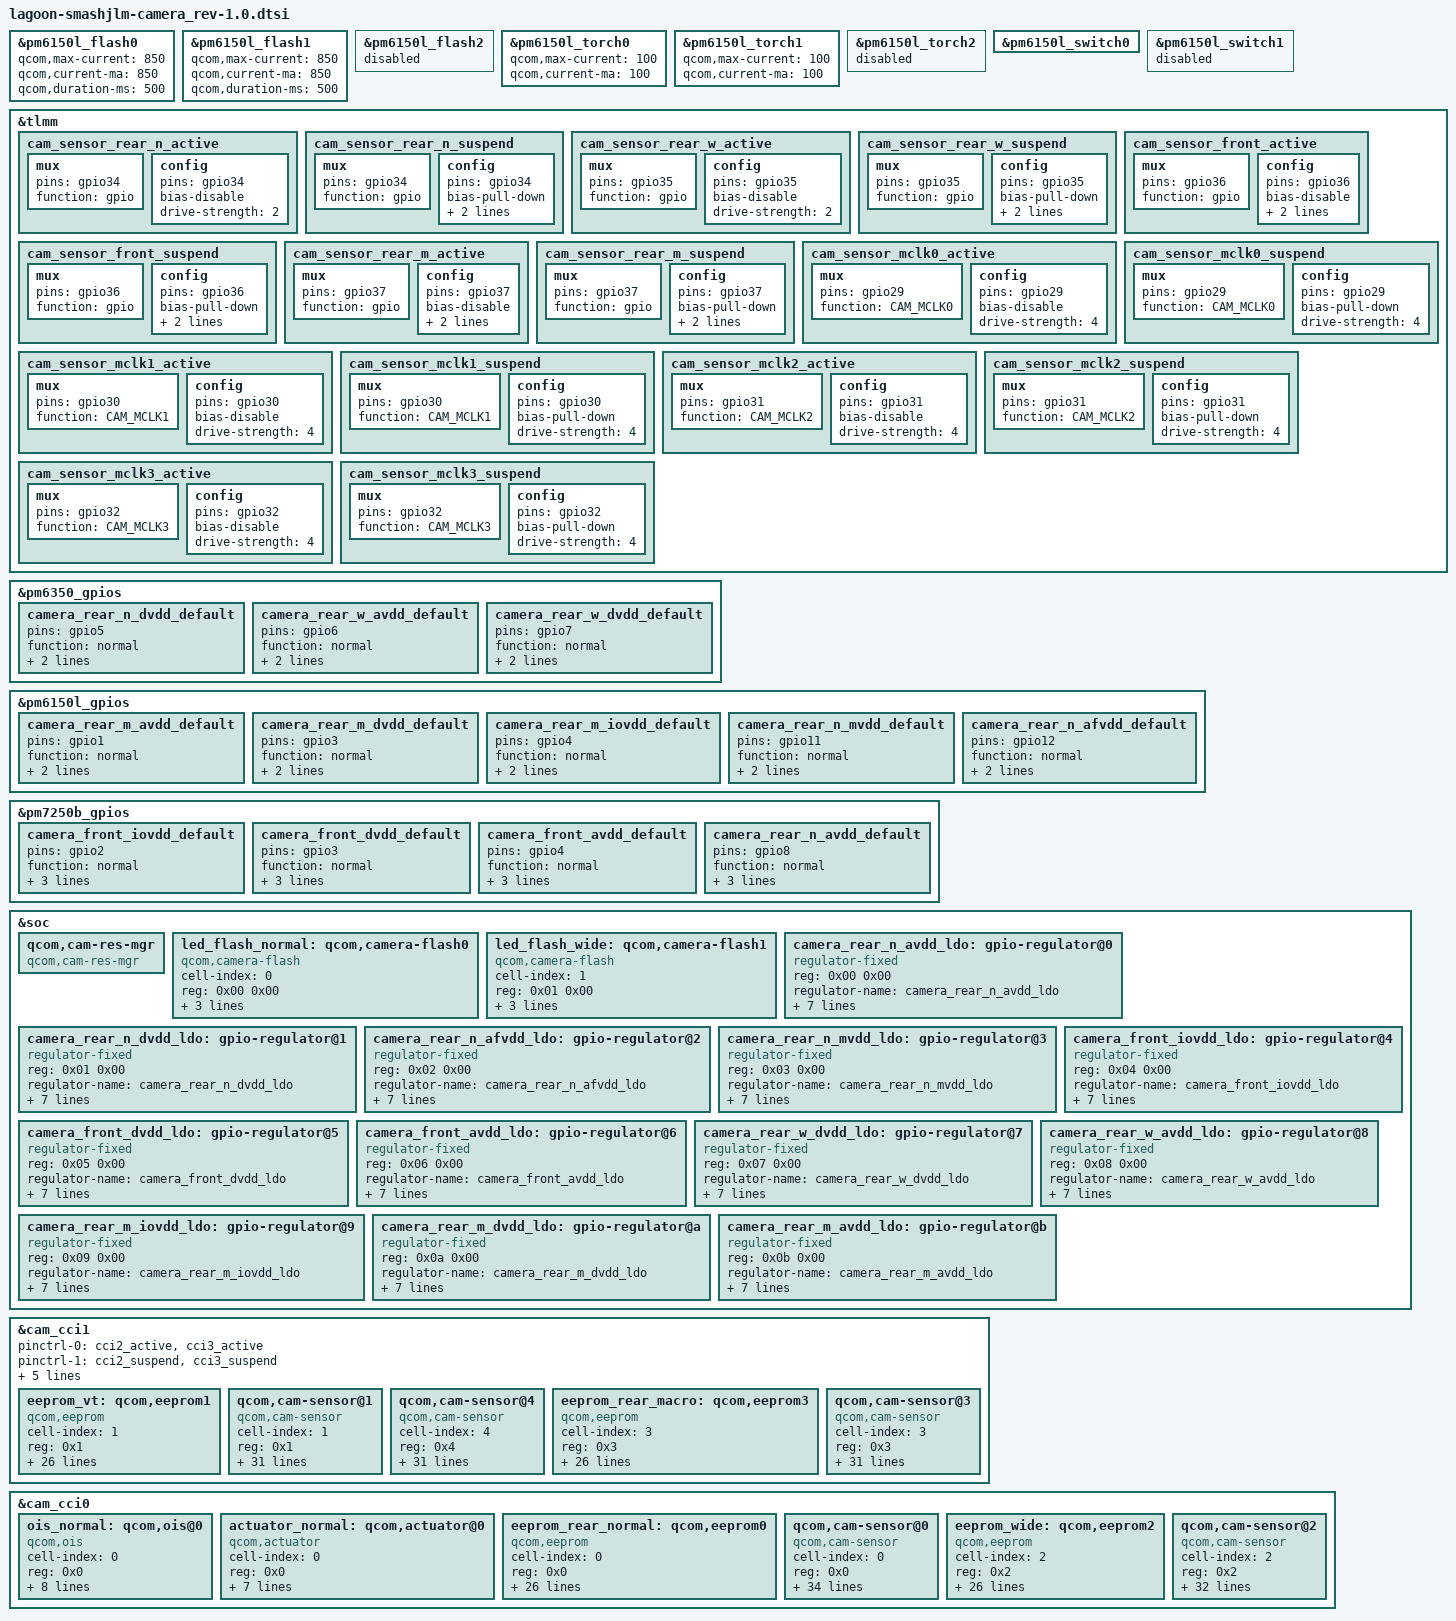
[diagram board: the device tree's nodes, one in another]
// SPDX-License-Identifier: GPL-2.0-only
/*
 * Copyright (c) 2018-2019, The Linux Foundation. All rights reserved.
 */

#include <dt-bindings/clock/qcom,camcc-lagoon.h>

&pm6150l_flash0 {
	status = "ok";
	qcom,max-current = <850>;
	qcom,current-ma = <850>;
	qcom,duration-ms = <500>;
};

&pm6150l_flash1 {
	status = "ok";
	qcom,max-current = <850>;
	qcom,current-ma = <850>;
	qcom,duration-ms = <500>;
};

&pm6150l_flash2 {
	status = "disabled";
};

&pm6150l_torch0 {
	status = "ok";
	qcom,max-current = <100>;
	qcom,current-ma = <100>;
};

&pm6150l_torch1 {
	status = "ok";
	qcom,max-current = <100>;
	qcom,current-ma = <100>;
};

&pm6150l_torch2 {
	status = "disabled";
};

&pm6150l_switch0 {
	status = "ok";
};

&pm6150l_switch1 {
	status = "disbled";
};

&tlmm{
	cam_sensor_rear_n_active: cam_sensor_rear_n_active {
		mux {
			pins = "gpio34";
			function = "gpio";
		};

		config {
			pins = "gpio34";
			bias-disable;
			drive-strength = <2>;
		};
	};

	cam_sensor_rear_n_suspend: cam_sensor_rear_n_suspend {
		mux {
			pins = "gpio34";
			function = "gpio";
		};

		config {
			pins = "gpio34";
			bias-pull-down;
			drive-strength = <2>;
			output-low;
		};
	};

	cam_sensor_rear_w_active: cam_sensor_rear_w_active {
		mux {
			pins = "gpio35";
			function = "gpio";
		};

		config {
			pins = "gpio35";
			bias-disable;
			drive-strength = <2>;
		};
	};

	cam_sensor_rear_w_suspend: cam_sensor_rear_w_suspend {
		mux {
			pins = "gpio35";
			function = "gpio";
		};

		config {
			pins = "gpio35";
			bias-pull-down;
			drive-strength = <2>;
			output-low;
		};
	};

	cam_sensor_front_active: cam_sensor_front_active {
		mux {
			pins = "gpio36";
			function = "gpio";
		};

		config {
			pins = "gpio36";
			bias-disable;
			drive-strength = <2>;
			output-low;
		};
	};

	cam_sensor_front_suspend: cam_sensor_front_suspend {
		mux {
			pins = "gpio36";
			function = "gpio";
		};

		config {
			pins = "gpio36";
			bias-pull-down;
			drive-strength = <2>;
			output-low;
		};
	};

	cam_sensor_rear_m_active: cam_sensor_rear_m_active {
		mux {
			pins = "gpio37";
			function = "gpio";
		};

		config {
			pins = "gpio37";
			bias-disable;
			drive-strength = <2>;
			output-low;
		};
	};

	cam_sensor_rear_m_suspend: cam_sensor_rear_m_suspend {
		mux {
			pins = "gpio37";
			function = "gpio";
		};

		config {
			pins = "gpio37";
			bias-pull-down;
			drive-strength = <2>;
			output-low;
		};
	};

	cam_sensor_mclk0_active: cam_sensor_mclk0_active {
		/* MCLK0 */
		mux {
			pins = "gpio29";
			function = "CAM_MCLK0";
		};

		config {
			pins = "gpio29";
			bias-disable; /* No PULL */
			drive-strength = <4>; /* To improve rising time (2ma->4ma)*/
		};
	};

	cam_sensor_mclk0_suspend: cam_sensor_mclk0_suspend {
		/* MCLK0 */
		mux {
			pins = "gpio29";
			function = "CAM_MCLK0";
		};

		config {
			pins = "gpio29";
			bias-pull-down; /* PULL DOWN */
			drive-strength = <4>; /* 4 MA */
		};
	};

	cam_sensor_mclk1_active: cam_sensor_mclk1_active {
		/* MCLK1 */
		mux {
			pins = "gpio30";
			function = "CAM_MCLK1";
		};

		config {
			pins = "gpio30";
			bias-disable; /* No PULL */
			drive-strength = <4>; /* 4 MA */
		};
	};

	cam_sensor_mclk1_suspend: cam_sensor_mclk1_suspend {
		/* MCLK1 */
		mux {
			pins = "gpio30";
			function = "CAM_MCLK1";
		};

		config {
			pins = "gpio30";
			bias-pull-down; /* PULL DOWN */
			drive-strength = <4>; /* 4 MA */
		};
	};

	cam_sensor_mclk2_active: cam_sensor_mclk2_active {
		/* MCLK2 */
		mux {
			pins = "gpio31";
			function = "CAM_MCLK2";
		};

		config {
			pins = "gpio31";
			bias-disable; /* No PULL */
			drive-strength = <4>; /* 4 MA */
		};
	};

	cam_sensor_mclk2_suspend: cam_sensor_mclk2_suspend {
		/* MCLK2 */
		mux {
			pins = "gpio31";
			function = "CAM_MCLK2";
		};

		config {
			pins = "gpio31";
			bias-pull-down; /* PULL DOWN */
			drive-strength = <4>; /* 4 MA */
		};
	};

	cam_sensor_mclk3_active: cam_sensor_mclk3_active {
		/* MCLK3 */
		mux {
			pins = "gpio32";
			function = "CAM_MCLK3";
		};

		config {
			pins = "gpio32";
			bias-disable; /* No PULL */
			drive-strength = <4>; /* 4 MA */
		};
	};

	cam_sensor_mclk3_suspend: cam_sensor_mclk3_suspend {
		/* MCLK3 */
		mux {
			pins = "gpio32";
			function = "CAM_MCLK3";
		};

		config {
			pins = "gpio32";
			bias-pull-down; /* PULL DOWN */
			drive-strength = <4>; /* 4 MA */
		};
	};
};

&pm6350_gpios {
	camera_rear_n_dvdd_default: camera_rear_n_dvdd_default {
		pins = "gpio5";
		function = "normal";
		power-source = <0>;
		output-high;
	};

	camera_rear_w_avdd_default: camera_rear_w_avdd_default {
		pins = "gpio6";
		function = "normal";
		power-source = <0>;
		output-high;
	};

	camera_rear_w_dvdd_default: camera_rear_w_dvdd_default {
		pins = "gpio7";
		function = "normal";
		power-source = <0>;
		output-high;
	};
};

&pm6150l_gpios {
	camera_rear_m_avdd_default: camera_rear_m_avdd_default {
		pins = "gpio1";
		function = "normal";
		power-source = <0>;
		output-high;
	};

	camera_rear_m_dvdd_default: camera_rear_m_dvdd_default {
		pins = "gpio3";
		function = "normal";
		power-source = <0>;
		output-high;
	};

	camera_rear_m_iovdd_default: camera_rear_m_iovdd_default {
		pins = "gpio4";
		function = "normal";
		power-source = <0>;
		output-high;
	};

	camera_rear_n_mvdd_default: camera_rear_n_mvdd_default {
		pins = "gpio11";
		function = "normal";
		power-source = <0>;
		output-high;
	};
	camera_rear_n_afvdd_default: camera_rear_n_afvdd_default {
		pins = "gpio12";
		function = "normal";
		power-source = <0>;
		output-high;
	};
};

&pm7250b_gpios {
	camera_front_iovdd_default: camera_front_iovdd_default {
		pins = "gpio2";
		function = "normal";
		power-source = <0>;
		input-disable;
		output-high;
	};

	camera_front_dvdd_default: camera_front_dvdd_default {
		pins = "gpio3";
		function = "normal";
		power-source = <0>;
		input-disable;
		output-high;
	};

	camera_front_avdd_default: camera_front_avdd_default {
		pins = "gpio4";
		function = "normal";
		power-source = <0>;
		input-disable;
		output-high;
	};

	camera_rear_n_avdd_default: camera_rear_n_avdd_default {
		pins = "gpio8";
		function = "normal";
		power-source = <0>;
		input-disable;
		output-high;
	};
};

&soc {
    qcom,cam-res-mgr {
        compatible = "qcom,cam-res-mgr";
        status = "ok";
    };

	led_flash_normal: qcom,camera-flash0 {
		cell-index = <0>;
		reg = <0x00 0x00>;
		compatible = "qcom,camera-flash";
		flash-source = <&pm6150l_flash0 &pm6150l_flash1>;
		torch-source = <&pm6150l_torch0 &pm6150l_torch1>;
		switch-source = <&pm6150l_switch2>;
		status = "ok";
	};

	led_flash_wide: qcom,camera-flash1 {
		cell-index = <1>;
		reg = <0x01 0x00>;
		compatible = "qcom,camera-flash";
		flash-source = <&pm6150l_flash0 &pm6150l_flash1>;
		torch-source = <&pm6150l_torch0 &pm6150l_torch1>;
		switch-source = <&pm6150l_switch2>;
		status = "ok";
	};

	camera_rear_n_avdd_ldo: gpio-regulator@0 {
		compatible = "regulator-fixed";
		reg = <0x00 0x00>;
		regulator-name = "camera_rear_n_avdd_ldo";
		regulator-min-microvolt = <2800000>;
		regulator-max-microvolt = <2800000>;
		regulator-enable-ramp-delay = <135>;
		enable-active-high;
		gpio = <&pm7250b_gpios 8 0>;
		pinctrl-names = "default";
		pinctrl-0 = <&camera_rear_n_avdd_default>;
		vin-supply = <&BOB>;
	};

	camera_rear_n_dvdd_ldo: gpio-regulator@1 {
		compatible = "regulator-fixed";
		reg = <0x01 0x00>;
		regulator-name = "camera_rear_n_dvdd_ldo";
		regulator-min-microvolt = <1050000>;
		regulator-max-microvolt = <1050000>;
		regulator-enable-ramp-delay = <135>;
		enable-active-high;
		gpio = <&pm6350_gpios 5 0>;
		pinctrl-names = "default";
		pinctrl-0 = <&camera_rear_n_dvdd_default>;
		vin-supply = <&S2A>;
	};

	camera_rear_n_afvdd_ldo: gpio-regulator@2 {
		compatible = "regulator-fixed";
		reg = <0x02 0x00>;
		regulator-name = "camera_rear_n_afvdd_ldo";
		regulator-min-microvolt = <2800000>;
		regulator-max-microvolt = <2800000>;
		regulator-enable-ramp-delay = <135>;
		enable-active-high;
		gpio = <&pm6150l_gpios 12 0>;
		pinctrl-names = "default";
		pinctrl-0 = <&camera_rear_n_afvdd_default>;
		vin-supply = <&BOB>;
	};

	camera_rear_n_mvdd_ldo: gpio-regulator@3 {
		compatible = "regulator-fixed";
		reg = <0x03 0x00>;
		regulator-name = "camera_rear_n_mvdd_ldo";
		regulator-min-microvolt = <2800000>;
		regulator-max-microvolt = <2800000>;
		regulator-enable-ramp-delay = <135>;
		enable-active-high;
		gpio = <&pm6150l_gpios 11 0>;
		pinctrl-names = "default";
		pinctrl-0 = <&camera_rear_n_mvdd_default>;
		vin-supply = <&BOB>;
	};

	camera_front_iovdd_ldo: gpio-regulator@4 {
		compatible = "regulator-fixed";
		reg = <0x04 0x00>;
		regulator-name = "camera_front_iovdd_ldo";
		regulator-min-microvolt = <1800000>;
		regulator-max-microvolt = <1800000>;
		regulator-enable-ramp-delay = <135>;
		enable-active-high;
		gpio = <&pm7250b_gpios 2 0>;
		pinctrl-names = "default";
		pinctrl-0 = <&camera_front_iovdd_default>;
		vin-supply = <&BOB>;
	};

	camera_front_dvdd_ldo: gpio-regulator@5 {
		compatible = "regulator-fixed";
		reg = <0x05 0x00>;
		regulator-name = "camera_front_dvdd_ldo";
		regulator-min-microvolt = <1050000>;
		regulator-max-microvolt = <1050000>;
		regulator-enable-ramp-delay = <135>;
		enable-active-high;
		gpio = <&pm7250b_gpios 3 0>;
		pinctrl-names = "default";
		pinctrl-0 = <&camera_front_dvdd_default>;
		vin-supply = <&S2A>;
	};

	camera_front_avdd_ldo: gpio-regulator@6 {
		compatible = "regulator-fixed";
		reg = <0x06 0x00>;
		regulator-name = "camera_front_avdd_ldo";
		regulator-min-microvolt = <2800000>;
		regulator-max-microvolt = <2800000>;
		regulator-enable-ramp-delay = <135>;
		enable-active-high;
		gpio = <&pm7250b_gpios 4 0>;
		pinctrl-names = "default";
		pinctrl-0 = <&camera_front_avdd_default>;
		vin-supply = <&BOB>;
	};

	camera_rear_w_dvdd_ldo: gpio-regulator@7 {
		compatible = "regulator-fixed";
		reg = <0x07 0x00>;
		regulator-name = "camera_rear_w_dvdd_ldo";
		regulator-min-microvolt = <1000000>;
		regulator-max-microvolt = <1000000>;
		regulator-enable-ramp-delay = <135>;
		enable-active-high;
		gpio = <&pm6350_gpios 7 0>;
		pinctrl-names = "default";
		pinctrl-0 = <&camera_rear_w_dvdd_default>;
		vin-supply = <&S2A>;
	};

	camera_rear_w_avdd_ldo: gpio-regulator@8 {
		compatible = "regulator-fixed";
		reg = <0x08 0x00>;
		regulator-name = "camera_rear_w_avdd_ldo";
		regulator-min-microvolt = <2800000>;
		regulator-max-microvolt = <2800000>;
		regulator-enable-ramp-delay = <135>;
		enable-active-high;
		gpio = <&pm6350_gpios 6 0>;
		pinctrl-names = "default";
		pinctrl-0 = <&camera_rear_w_avdd_default>;
		vin-supply = <&BOB>;
	};

	camera_rear_m_iovdd_ldo: gpio-regulator@9 {
		compatible = "regulator-fixed";
		reg = <0x09 0x00>;
		regulator-name = "camera_rear_m_iovdd_ldo";
		regulator-min-microvolt = <1800000>;
		regulator-max-microvolt = <1800000>;
		regulator-enable-ramp-delay = <135>;
		enable-active-high;
		gpio = <&pm6150l_gpios 4 0>;
		pinctrl-names = "default";
		pinctrl-0 = <&camera_rear_m_iovdd_default>;
		vin-supply = <&BOB>;
	};

	camera_rear_m_dvdd_ldo: gpio-regulator@a {
		compatible = "regulator-fixed";
		reg = <0x0a 0x00>;
		regulator-name = "camera_rear_m_dvdd_ldo";
		regulator-min-microvolt = <1800000>;
		regulator-max-microvolt = <1800000>;
		regulator-enable-ramp-delay = <135>;
		enable-active-high;
		gpio = <&pm6150l_gpios 3 0>;
		pinctrl-names = "default";
		pinctrl-0 = <&camera_rear_m_dvdd_default>;
		vin-supply = <&BOB>;
	};

	camera_rear_m_avdd_ldo: gpio-regulator@b {
		compatible = "regulator-fixed";
		reg = <0x0b 0x00>;
		regulator-name = "camera_rear_m_avdd_ldo";
		regulator-min-microvolt = <2800000>;
		regulator-max-microvolt = <2800000>;
		regulator-enable-ramp-delay = <135>;
		enable-active-high;
		gpio = <&pm6150l_gpios 1 0>;
		pinctrl-names = "default";
		pinctrl-0 = <&camera_rear_m_avdd_default>;
		vin-supply = <&BOB>;
	};
};

&cam_cci1 {
    pinctrl-0 = <&cci2_active &cci3_active>;
    pinctrl-1 = <&cci2_suspend &cci3_suspend>;
    gpios = <&tlmm 43 0>,
        <&tlmm 44 0>,
        <&tlmm 2 0>,
        <&tlmm 3 0>;
    gpio-req-tbl-num = <0 1 2 3>;
    gpio-req-tbl-flags = <1 1 1 1>;
    gpio-req-tbl-label = "CCI_I2C_DATA2",
                "CCI_I2C_CLK2",
                "CCI_I2C_DATA3",
                "CCI_I2C_CLK3";
};

&cam_cci0 {
	ois_normal: qcom,ois@0 {
		cell-index = <0>;
		reg = <0x0>;
		compatible = "qcom,ois";
		cci-master = <0>;
		cam_vaf-supply = <&camera_rear_n_afvdd_ldo>;
		cam_v_custom1-supply = <&camera_rear_n_mvdd_ldo>;
		regulator-names = "cam_vaf","cam_v_custom1";
		rgltr-cntrl-support;
		rgltr-min-voltage = <2800000 2800000>;
		rgltr-max-voltage = <2800000 2800000>;
		rgltr-load-current = <0 0>;
		status = "ok";
	};

    actuator_normal: qcom,actuator@0 {
		cell-index = <0>;
		reg = <0x0>;
		compatible = "qcom,actuator";
		cci-master = <0>;
		cam_vaf-supply = <&camera_rear_n_afvdd_ldo>;
		rgltr-cntrl-support;
		regulator-names = "cam_vaf";
		rgltr-min-voltage = <2800000>;
		rgltr-max-voltage = <2800000>;
		rgltr-load-current = <0>;
		status = "ok";
	};

	eeprom_rear_normal: qcom,eeprom0 {
		cell-index = <0>;
		reg = <0x0>;
		compatible = "qcom,eeprom";
		cam_vio-supply = <&L9A>;
		cam_vana-supply = <&camera_rear_n_avdd_ldo>;
		cam_vdig-supply = <&camera_rear_n_dvdd_ldo>;
		cam_clk-supply = <&cam_cc_titan_top_gdsc>;
		regulator-names = "cam_vio", "cam_vana", "cam_vdig", "cam_clk";
		rgltr-cntrl-support;
		rgltr-min-voltage = <1800000 2800000 1050000 0>;
		rgltr-max-voltage = <1800000 2800000 1050000 0>;
		rgltr-load-current = <150000 150000 300000 0>;
		gpio-no-mux = <0>;
		pinctrl-names = "cam_default", "cam_suspend";
		pinctrl-0 = <&cam_sensor_mclk0_active
				 &cam_sensor_rear_n_active>;
		pinctrl-1 = <&cam_sensor_mclk0_suspend
				 &cam_sensor_rear_n_suspend>;
		gpios = <&tlmm 29 0>,
			<&tlmm 34 0>;
		gpio-reset = <1>;
		gpio-req-tbl-num = <0 1>;
		gpio-req-tbl-flags = <1 0>;
		gpio-req-tbl-label = "CAMIF_MCLK0",
					"CAM_RESET0";
		sensor-position = <0>;
		sensor-mode = <0>;
		cci-master = <0>;
		status = "ok";
		clocks = <&camcc CAM_CC_MCLK0_CLK>;
		clock-names = "cam_clk";
		clock-cntl-level = "turbo";
		clock-rates = <19200000>;
	};

	qcom,cam-sensor@0 {
		cell-index = <0>;
		compatible = "qcom,cam-sensor";
		reg = <0x0>;
		csiphy-sd-index = <0>;
		sensor-position-roll = <90>;
		sensor-position-pitch = <0>;
		sensor-position-yaw = <180>;
		ois-src = <&ois_normal>;
		eeprom-src = <&eeprom_rear_normal>;
		actuator-src = <&actuator_normal>;
		led-flash-src = <&led_flash_normal>;
		cam_vio-supply = <&L9A>;
		cam_vana-supply = <&camera_rear_n_avdd_ldo>;
		cam_vdig-supply = <&camera_rear_n_dvdd_ldo>;
		cam_clk-supply = <&cam_cc_titan_top_gdsc>;
		regulator-names = "cam_vio", "cam_vana", "cam_vdig", "cam_clk";
		rgltr-cntrl-support;
		rgltr-min-voltage = <1800000 2800000 1050000 0>;
		rgltr-max-voltage = <1800000 2800000 1050000 0>;
		rgltr-load-current = <150000 150000 300000 0>;
		gpio-no-mux = <0>;
		pinctrl-names = "cam_default", "cam_suspend";
		pinctrl-0 = <&cam_sensor_mclk0_active
				 &cam_sensor_rear_n_active>;
		pinctrl-1 = <&cam_sensor_mclk0_suspend
				 &cam_sensor_rear_n_suspend>;
		gpios = <&tlmm 29 0>,
			<&tlmm 34 0>;
		gpio-reset = <1>;
		gpio-req-tbl-num = <0 1>;
		gpio-req-tbl-flags = <1 0>;
		gpio-req-tbl-label = "CAMIF_MCLK0",
					"CAM_RESET0";
		sensor-mode = <0>;
		cci-device = <0>;
		cci-master = <0>;
		status = "ok";
		clocks = <&camcc CAM_CC_MCLK0_CLK>;
		clock-names = "cam_clk";
		clock-cntl-level = "turbo";
		clock-rates = <19200000>;
	};

	eeprom_wide: qcom,eeprom2 {
		cell-index = <2>;
		reg = <0x2>;
		compatible = "qcom,eeprom";
		cam_vio-supply = <&L9A>;
		cam_vana-supply = <&camera_rear_w_avdd_ldo>;
		cam_vdig-supply = <&camera_rear_w_dvdd_ldo>;
		cam_clk-supply = <&cam_cc_titan_top_gdsc>;
		regulator-names = "cam_vio", "cam_vana", "cam_vdig", "cam_clk";
		rgltr-cntrl-support;
		rgltr-min-voltage = <1800000 2800000 1000000 0>;
		rgltr-max-voltage = <1800000 2800000 1000000 0>;
		rgltr-load-current = <150000 150000 300000 0>;
		gpio-no-mux = <0>;
		pinctrl-names = "cam_default", "cam_suspend";
		pinctrl-0 = <&cam_sensor_mclk1_active
				&cam_sensor_rear_w_active>;
		pinctrl-1 = <&cam_sensor_mclk1_suspend
				&cam_sensor_rear_w_suspend>;
		gpios = <&tlmm 30 0>,
			<&tlmm 35 0>;
		gpio-reset = <1>;
		gpio-req-tbl-num = <0 1>;
		gpio-req-tbl-flags = <1 0>;
		gpio-req-tbl-label = "CAMIF_MCLK1",
					"CAM_RESET1";
                sensor-position = <0>;
		sensor-mode = <0>;
		cci-master = <1>;
		status = "ok";
		clocks = <&camcc CAM_CC_MCLK1_CLK>;
		clock-names = "cam_clk";
		clock-cntl-level = "turbo";
		clock-rates = <19200000>;
	};

	qcom,cam-sensor@2 {
		cell-index = <2>;
		compatible = "qcom,cam-sensor";
		reg = <0x2>;
		csiphy-sd-index = <1>;
		sensor-position-roll = <90>;
		sensor-position-pitch = <0>;
		sensor-position-yaw = <180>;
		led-flash-src = <&led_flash_wide>;
		eeprom-src = <&eeprom_wide>;
		cam_vio-supply = <&L9A>;
		cam_vana-supply = <&camera_rear_w_avdd_ldo>;
		cam_vdig-supply = <&camera_rear_w_dvdd_ldo>;
		cam_clk-supply = <&cam_cc_titan_top_gdsc>;
		regulator-names = "cam_vio", "cam_vana", "cam_vdig", "cam_clk";
		rgltr-cntrl-support;
		rgltr-min-voltage = <1800000 2800000 1000000 0>;
		rgltr-max-voltage = <1800000 2800000 1000000 0>;
		rgltr-load-current = <150000 150000 300000 0>;
		gpio-no-mux = <0>;
		pinctrl-names = "cam_default", "cam_suspend";
		pinctrl-0 = <&cam_sensor_mclk1_active
				&cam_sensor_rear_w_active>;
		pinctrl-1 = <&cam_sensor_mclk1_suspend
				&cam_sensor_rear_w_suspend>;
		gpios = <&tlmm 30 0>,
			<&tlmm 35 0>;
		gpio-reset = <1>;
		gpio-req-tbl-num = <0 1>;
		gpio-req-tbl-flags = <1 0>;
		gpio-req-tbl-label = "CAMIF_MCLK1",
					"CAM_RESET1";
		sensor-mode = <0>;
		cci-device = <0>;
		cci-master = <1>;
		status = "ok";
		clocks = <&camcc CAM_CC_MCLK1_CLK>;
		clock-names = "cam_clk";
		clock-cntl-level = "turbo";
		clock-rates = <19200000>;
	};

};

&cam_cci1 {
	eeprom_vt: qcom,eeprom1 {
		cell-index = <1>;
		reg = <0x1>;
		compatible = "qcom,eeprom";
		cam_vio-supply = <&camera_front_iovdd_ldo>;
		cam_vana-supply = <&camera_front_avdd_ldo>;
		cam_vdig-supply = <&camera_front_dvdd_ldo>;
		cam_clk-supply = <&cam_cc_titan_top_gdsc>;
		regulator-names = "cam_vio", "cam_vana", "cam_vdig", "cam_clk";
		rgltr-cntrl-support;
		rgltr-min-voltage = <1800000 2800000 1050000 0>;
		rgltr-max-voltage = <1800000 2800000 1050000 0>;
		rgltr-load-current = <150000 150000 150000 0>;
		gpio-no-mux = <0>;
		pinctrl-names = "cam_default", "cam_suspend";
		pinctrl-0 = <&cam_sensor_mclk2_active
				 &cam_sensor_front_active>;
		pinctrl-1 = <&cam_sensor_mclk2_suspend
				 &cam_sensor_front_suspend>;
		gpios = <&tlmm 31 0>,
			<&tlmm 36 0>;
		gpio-reset = <1>;
		gpio-req-tbl-num = <0 1>;
		gpio-req-tbl-flags = <1 0>;
		gpio-req-tbl-label = "VT_MCLK",
					"VT_RESET";
		sensor-position = <0>;
		sensor-mode = <0>;
		cci-master = <0>;
		status = "ok";
		clocks = <&camcc CAM_CC_MCLK2_CLK>;
		clock-names = "cam_clk";
		clock-cntl-level = "turbo";
		clock-rates = <19200000>;
	};

	qcom,cam-sensor@1 {
		cell-index = <1>;
		compatible = "qcom,cam-sensor";
		reg = <0x1>;
		csiphy-sd-index = <2>;
		sensor-position-roll = <270>;
		sensor-position-pitch = <0>;
		sensor-position-yaw = <0>;
		eeprom-src = <&eeprom_vt>;
		cam_vio-supply = <&camera_front_iovdd_ldo>;
		cam_vana-supply = <&camera_front_avdd_ldo>;
		cam_vdig-supply = <&camera_front_dvdd_ldo>;
		cam_clk-supply = <&cam_cc_titan_top_gdsc>;
		regulator-names = "cam_vio", "cam_vana", "cam_vdig", "cam_clk";
		rgltr-cntrl-support;
		rgltr-min-voltage = <1800000 2800000 1050000 0>;
		rgltr-max-voltage = <1800000 2800000 1050000 0>;
		rgltr-load-current = <150000 150000 150000 0>;
		gpio-no-mux = <0>;
		pinctrl-names = "cam_default", "cam_suspend";
		pinctrl-0 = <&cam_sensor_mclk2_active
				 &cam_sensor_front_active>;
		pinctrl-1 = <&cam_sensor_mclk2_suspend
				 &cam_sensor_front_suspend>;
		gpios = <&tlmm 31 0>,
			<&tlmm 36 0>;
		gpio-reset = <1>;
		gpio-req-tbl-num = <0 1>;
		gpio-req-tbl-flags = <1 0>;
		gpio-req-tbl-label = "VT_MCLK",
					"VT_RESET";
		sensor-mode = <0>;
		cci-device = <1>;
		cci-master = <0>;
		status = "ok";
		clocks = <&camcc CAM_CC_MCLK2_CLK>;
		clock-names = "cam_clk";
		clock-cntl-level = "turbo";
		clock-rates = <19200000>;
	};
	qcom,cam-sensor@4 {
		cell-index = <4>;
		compatible = "qcom,cam-sensor";
		reg = <0x4>;
		csiphy-sd-index = <2>;
		sensor-position-roll = <90>;
		sensor-position-pitch = <0>;
		sensor-position-yaw = <0>;
		eeprom-src = <&eeprom_vt>;
		cam_vio-supply = <&camera_front_iovdd_ldo>;
		cam_vana-supply = <&camera_front_avdd_ldo>;
		cam_vdig-supply = <&camera_front_dvdd_ldo>;
		cam_clk-supply = <&cam_cc_titan_top_gdsc>;
		regulator-names = "cam_vio", "cam_vana", "cam_vdig", "cam_clk";
		rgltr-cntrl-support;
		rgltr-min-voltage = <1800000 2800000 1050000 0>;
		rgltr-max-voltage = <1800000 2800000 1050000 0>;
		rgltr-load-current = <150000 150000 150000 0>;
		gpio-no-mux = <0>;
		pinctrl-names = "cam_default", "cam_suspend";
		pinctrl-0 = <&cam_sensor_mclk2_active
				 &cam_sensor_front_active>;
		pinctrl-1 = <&cam_sensor_mclk2_suspend
				 &cam_sensor_front_suspend>;
		gpios = <&tlmm 31 0>,
			<&tlmm 36 0>;
		gpio-reset = <1>;
		gpio-req-tbl-num = <0 1>;
		gpio-req-tbl-flags = <1 0>;
		gpio-req-tbl-label = "VT_MCLK",
					"VT_RESET";
		sensor-mode = <0>;
		cci-device = <1>;
		cci-master = <0>;
		status = "ok";
		clocks = <&camcc CAM_CC_MCLK2_CLK>;
		clock-names = "cam_clk";
		clock-cntl-level = "turbo";
		clock-rates = <19200000>;
	};
	eeprom_rear_macro: qcom,eeprom3 {
		cell-index = <3>;
		reg = <0x3>;
		compatible = "qcom,eeprom";
		cam_vio-supply = <&camera_rear_m_iovdd_ldo>;
		cam_vana-supply = <&camera_rear_m_avdd_ldo>;
		cam_vdig-supply = <&camera_rear_m_dvdd_ldo>;
		cam_clk-supply = <&cam_cc_titan_top_gdsc>;
		regulator-names = "cam_vio", "cam_vana", "cam_vdig", "cam_clk";
		rgltr-cntrl-support;
		rgltr-min-voltage = <1800000 2800000 1800000 0>;
		rgltr-max-voltage = <1800000 2800000 1800000 0>;
		rgltr-load-current = <150000 150000 150000 0>;
		gpio-no-mux = <0>;
		pinctrl-names = "cam_default", "cam_suspend";
		pinctrl-0 = <&cam_sensor_mclk3_active
				 &cam_sensor_rear_m_active>;
		pinctrl-1 = <&cam_sensor_mclk3_suspend
				 &cam_sensor_rear_m_suspend>;
		gpios = <&tlmm 32 0>,
			<&tlmm 37 0>;
		gpio-reset = <1>;
		gpio-req-tbl-num = <0 1>;
		gpio-req-tbl-flags = <1 0>;
		gpio-req-tbl-label = "MACRO_MCLK",
					"MACRO_RESET";
                sensor-position = <0>;
		sensor-mode = <0>;
		cci-master = <1>;
		status = "ok";
		clocks = <&camcc CAM_CC_MCLK3_CLK>;
		clock-names = "cam_clk";
		clock-cntl-level = "turbo";
		clock-rates = <19200000>;
	};

	qcom,cam-sensor@3 {
		cell-index = <3>;
		compatible = "qcom,cam-sensor";
		reg = <0x3>;
		csiphy-sd-index = <3>;
		sensor-position-roll = <90>;
		sensor-position-pitch = <0>;
		sensor-position-yaw = <180>;
		eeprom-src = <&eeprom_rear_macro>;
		cam_vio-supply = <&camera_rear_m_iovdd_ldo>;
		cam_vana-supply = <&camera_rear_m_avdd_ldo>;
		cam_vdig-supply = <&camera_rear_m_dvdd_ldo>;
		cam_clk-supply = <&cam_cc_titan_top_gdsc>;
		regulator-names = "cam_vio", "cam_vana", "cam_vdig", "cam_clk";
		rgltr-cntrl-support;
		rgltr-min-voltage = <1800000 2800000 1800000 0>;
		rgltr-max-voltage = <1800000 2800000 1800000 0>;
		rgltr-load-current = <150000 150000 150000 0>;
		gpio-no-mux = <0>;
		pinctrl-names = "cam_default", "cam_suspend";
		pinctrl-0 = <&cam_sensor_mclk3_active
				 &cam_sensor_rear_m_active>;
		pinctrl-1 = <&cam_sensor_mclk3_suspend
				 &cam_sensor_rear_m_suspend>;
		gpios = <&tlmm 32 0>,
			<&tlmm 37 0>;
		gpio-reset = <1>;
		gpio-req-tbl-num = <0 1>;
		gpio-req-tbl-flags = <1 0>;
		gpio-req-tbl-label = "MACRO_MCLK",
					"MACRO_RESET";
		sensor-mode = <0>;
		cci-device = <1>;
		cci-master = <1>;
		status = "ok";
		clocks = <&camcc CAM_CC_MCLK3_CLK>;
		clock-names = "cam_clk";
		clock-cntl-level = "turbo";
		clock-rates = <19200000>;
	};
};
